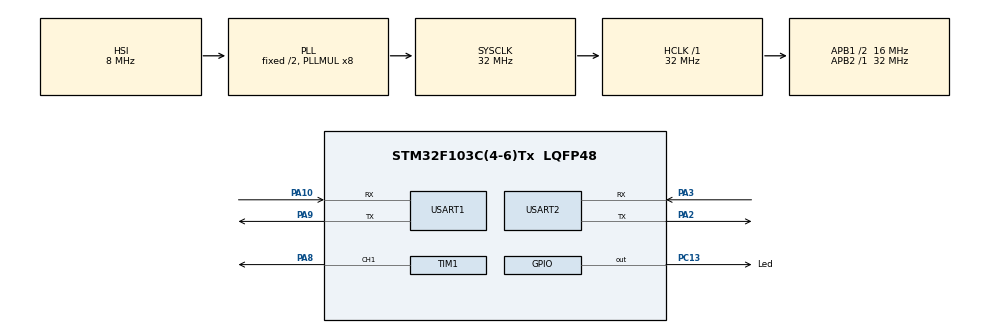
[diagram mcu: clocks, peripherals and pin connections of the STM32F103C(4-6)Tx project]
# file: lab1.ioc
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Mcu.Family=STM32F1
Mcu.Name=STM32F103C(4-6)Tx
Mcu.Package=LQFP48
NVIC.PriorityGroup=NVIC_PRIORITYGROUP_4
NVIC.TIM2_IRQn=true\:0\:0\:false\:false\:true\:true\:true\:true
NVIC.USART1_IRQn=true\:0\:0\:false\:false\:true\:true\:true\:true
NVIC.USART2_IRQn=true\:0\:0\:false\:false\:true\:true\:true\:true
PA10.Mode=Asynchronous
PA10.Signal=USART1_RX
PA13.Mode=JTAG_4_pins
PA13.Signal=SYS_JTMS-SWDIO
PA14.Mode=JTAG_4_pins
PA14.Signal=SYS_JTCK-SWCLK
PA15.Mode=JTAG_4_pins
PA15.Signal=SYS_JTDI
PA2.Mode=Asynchronous
PA2.Signal=USART2_TX
PA3.Mode=Asynchronous
PA3.Signal=USART2_RX
PA8.Signal=S_TIM1_CH1
PA9.Mode=Asynchronous
PA9.Signal=USART1_TX
PB3.Mode=JTAG_4_pins
PB3.Signal=SYS_JTDO-TRACESWO
PC13-TAMPER-RTC.GPIO_Label=Led
PC13-TAMPER-RTC.Signal=GPIO_Output
PC14-OSC32_IN.Mode=LSE-External-Oscillator
PC14-OSC32_IN.Signal=RCC_OSC32_IN
PC15-OSC32_OUT.Mode=LSE-External-Oscillator
PC15-OSC32_OUT.Signal=RCC_OSC32_OUT
PD0-OSC_IN.Mode=HSE-External-Oscillator
PD0-OSC_IN.Signal=RCC_OSC_IN
PD1-OSC_OUT.Mode=HSE-External-Oscillator
PD1-OSC_OUT.Signal=RCC_OSC_OUT
ProjectManager.HeapSize=0x200
ProjectManager.StackSize=0x400
ProjectManager.TargetToolchain=STM32CubeIDE
RCC.AHBFreq_Value=32000000
RCC.APB1CLKDivider=RCC_HCLK_DIV2
RCC.APB1Freq_Value=16000000
RCC.APB1TimFreq_Value=32000000
RCC.APB2Freq_Value=32000000
RCC.APB2TimFreq_Value=32000000
RCC.HCLKFreq_Value=32000000
RCC.HSE_VALUE=16000000
RCC.PLLMUL=RCC_PLL_MUL8
RCC.SYSCLKFreq_VALUE=32000000
RCC.SYSCLKSource=RCC_SYSCLKSOURCE_PLLCLK
RCC.USBFreq_Value=32000000
SH.S_TIM1_CH1.0=TIM1_CH1,PWM Generation1 CH1
TIM1.Channel-PWM\ Generation1\ CH1=TIM_CHANNEL_1
USART1.VirtualMode=VM_ASYNC
USART2.VirtualMode=VM_ASYNC
VP_TIM1_VS_ClockSourceINT.Mode=Internal
VP_TIM2_VS_ClockSourceINT.Mode=Internal
board=custom

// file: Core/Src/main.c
/* USER CODE BEGIN Header */
/**
  ******************************************************************************
  * @file           : main.c
  * @brief          : Main program body
  ******************************************************************************
  * @attention
  *
  * Copyright (c) 2024 STMicroelectronics.
  * All rights reserved.
  *
  * This software is licensed under terms that can be found in the LICENSE file
  * in the root directory of this software component.
  * If no LICENSE file comes with this software, it is provided AS-IS.
  *
  ******************************************************************************
  */
/* USER CODE END Header */
#include "main.h"
#include "tim.h"
#include "usart.h"
#include "gpio.h"
#include "string.h"
#include <stdbool.h>

void SystemClock_Config(void);

int main(void)
{
  /* USER CODE BEGIN 1 */
	uint8_t str[] = "Enter PASSWORD BRO\n";
	volatile uint8_t str1[] = "True";
	volatile uint8_t str2[] = "False";
	bool flg = 0;
	uint8_t rx_buff[6] = {0x0, 0x0, 0x0, 0x0, 0x0, 0x0};
  /* USER CODE END 1 */

  /* MCU Configuration--------------------------------------------------------*/

  /* Reset of all peripherals, Initializes the Flash interface and the Systick. */
  HAL_Init();

  /* Configure the system clock */
  SystemClock_Config();

  /* Initialize all configured peripherals */
  MX_GPIO_Init();
  MX_TIM1_Init();
  MX_TIM2_Init();
  MX_USART1_UART_Init();
  MX_USART2_UART_Init();
  /* USER CODE BEGIN 2 */
HAL_TIM_Base_Start_IT(&htim1);
HAL_TIM_Base_Start_IT(&huart1);
HAL_TIM_Base_Start_IT(&huart2);

  /* USER CODE END 2 */
uint8_t	count = 0;
  /* Infinite loop */
  /* USER CODE BEGIN WHILE */
goto mark;

mark: {

	for(int i = 0; i <=5; i ++) rx_buff[i] = 0;
	*rx_buff = 0;

	HAL_UART_Transmit(&huart1,"Enter pass\r",11,60);
	HAL_UART_Receive_IT(&huart1,rx_buff,6);
	while ((USART1->SR & USART_SR_RXNE)==0) ;
		HAL_Delay(1);
	if (!strncmp(rx_buff, "123456", 6)){
		HAL_UART_Transmit(&huart1,"true\r",5,60);
	HAL_GPIO_WritePin(GPIOC,GPIO_PIN_13,GPIO_PIN_RESET);
	}
	else if(strncmp(rx_buff, "123456", 6) || sizeof(rx_buff) > 6)
	{
		HAL_UART_Transmit(&huart1,"false\r",6,60);
	HAL_GPIO_WritePin(GPIOC,GPIO_PIN_13,GPIO_PIN_SET);
	}

	goto mark;
}
//	HAL_UART_Transmit(&huart1,str,sizeof(str),30);

//	HAL_UART_Receive_IT(&huart1,rx_buff,6);

//	if (!strncmp(rx_buff, "123456", 6))
//		count = 1;
//
//	else if (strncmp(rx_buff, "123456", 6))
//		count = 0;
//
//	else count = 2;
//
//	 HAL_UART_Transmit(&huart1,count,sizeof(count),30);
  while (1){

//	  while ((USART1->SR & USART_SR_RXNE)==0);
//	  HAL_Delay(1);
//	  HAL_UART_Receive_IT(&huart1,rx_buff,6);
//	  	if (!strncmp(rx_buff,"123456", 6))
//	  		HAL_UART_Transmit(&huart1,"true",4,30);
//	  	else
//	  		HAL_UART_Transmit(&huart1,"false",5,30);
//	  HAL_Delay(500);

//	  HAL_UART_Receive_IT(&huart1,rx_buff,6);
//	  if (!strncmp(rx_buff, "123456", 6) && count == 1){
//	  	  HAL_UART_Transmit(&huart1,str1,sizeof(str1),30);
//	  	  count = 2;
//	  }
//	  else if (strncmp(rx_buff, "123456", 6) && count == 0){
//		  HAL_UART_Transmit(&huart1,str2,sizeof(str2),30);
//		  count = 2;
//	  }
  }

}

void SystemClock_Config(void)
{
  RCC_OscInitTypeDef RCC_OscInitStruct = {0};
  RCC_ClkInitTypeDef RCC_ClkInitStruct = {0};

  /** Initializes the RCC Oscillators according to the specified parameters
  * in the RCC_OscInitTypeDef structure.
  */
  RCC_OscInitStruct.OscillatorType = RCC_OSCILLATORTYPE_HSI;
  RCC_OscInitStruct.HSIState = RCC_HSI_ON;
  RCC_OscInitStruct.HSICalibrationValue = RCC_HSICALIBRATION_DEFAULT;
  RCC_OscInitStruct.PLL.PLLState = RCC_PLL_ON;
  RCC_OscInitStruct.PLL.PLLSource = RCC_PLLSOURCE_HSI_DIV2;
  RCC_OscInitStruct.PLL.PLLMUL = RCC_PLL_MUL8;
  if (HAL_RCC_OscConfig(&RCC_OscInitStruct) != HAL_OK)
  {
    Error_Handler();
  }

  /** Initializes the CPU, AHB and APB buses clocks
  */
  RCC_ClkInitStruct.ClockType = RCC_CLOCKTYPE_HCLK|RCC_CLOCKTYPE_SYSCLK
                              |RCC_CLOCKTYPE_PCLK1|RCC_CLOCKTYPE_PCLK2;
  RCC_ClkInitStruct.SYSCLKSource = RCC_SYSCLKSOURCE_PLLCLK;
  RCC_ClkInitStruct.AHBCLKDivider = RCC_SYSCLK_DIV1;
  RCC_ClkInitStruct.APB1CLKDivider = RCC_HCLK_DIV2;
  RCC_ClkInitStruct.APB2CLKDivider = RCC_HCLK_DIV1;

  if (HAL_RCC_ClockConfig(&RCC_ClkInitStruct, FLASH_LATENCY_1) != HAL_OK)
  {
    Error_Handler();
  }
}

void Error_Handler(void)
{
  __disable_irq();
  while (1)
  {
  }
}
